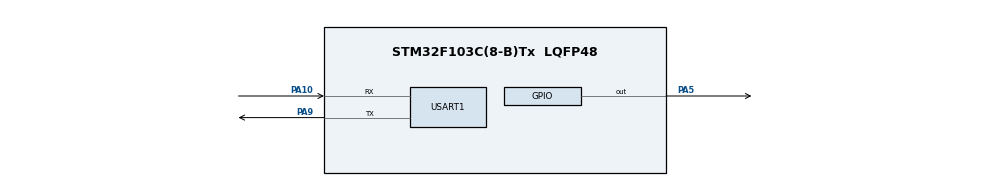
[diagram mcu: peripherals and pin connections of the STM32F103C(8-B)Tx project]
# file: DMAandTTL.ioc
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Dma.Request0=USART1_TX
Dma.Request1=USART1_RX
Dma.USART1_RX.1.Direction=DMA_PERIPH_TO_MEMORY
Dma.USART1_RX.1.Instance=DMA1_Channel5
Dma.USART1_RX.1.MemDataAlignment=DMA_MDATAALIGN_BYTE
Dma.USART1_RX.1.MemInc=DMA_MINC_ENABLE
Dma.USART1_RX.1.Mode=DMA_NORMAL
Dma.USART1_RX.1.PeriphDataAlignment=DMA_PDATAALIGN_BYTE
Dma.USART1_RX.1.PeriphInc=DMA_PINC_DISABLE
Dma.USART1_RX.1.Priority=DMA_PRIORITY_LOW
Dma.USART1_TX.0.Direction=DMA_MEMORY_TO_PERIPH
Dma.USART1_TX.0.Instance=DMA1_Channel4
Dma.USART1_TX.0.MemDataAlignment=DMA_MDATAALIGN_BYTE
Dma.USART1_TX.0.MemInc=DMA_MINC_ENABLE
Dma.USART1_TX.0.Mode=DMA_NORMAL
Dma.USART1_TX.0.PeriphDataAlignment=DMA_PDATAALIGN_BYTE
Dma.USART1_TX.0.PeriphInc=DMA_PINC_DISABLE
Dma.USART1_TX.0.Priority=DMA_PRIORITY_LOW
Mcu.Family=STM32F1
Mcu.Name=STM32F103C(8-B)Tx
Mcu.Package=LQFP48
NVIC.DMA1_Channel4_IRQn=true\:0\:0\:false\:false\:true\:false\:true\:true
NVIC.DMA1_Channel5_IRQn=true\:0\:0\:false\:false\:true\:false\:true\:true
NVIC.PriorityGroup=NVIC_PRIORITYGROUP_4
NVIC.USART1_IRQn=true\:0\:0\:false\:false\:true\:false\:true\:true
PA10.Mode=Asynchronous
PA10.Signal=USART1_RX
PA13.Mode=Serial_Wire
PA13.Signal=SYS_JTMS-SWDIO
PA14.Mode=Serial_Wire
PA14.Signal=SYS_JTCK-SWCLK
PA5.GPIO_ModeDefaultOutputPP=GPIO_MODE_OUTPUT_PP
PA5.GPIO_PuPd=GPIO_NOPULL
PA5.PinState=GPIO_PIN_SET
PA5.Signal=GPIO_Output
PA9.Mode=Asynchronous
PA9.Signal=USART1_TX
ProjectManager.HeapSize=0x200
ProjectManager.StackSize=0x400
ProjectManager.TargetToolchain=CMake
RCC.APB1Freq_Value=8000000
RCC.APB2Freq_Value=8000000
USART1.VirtualMode=VM_ASYNC
board=custom

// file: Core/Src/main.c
/* USER CODE BEGIN Header */
/**
  ******************************************************************************
  * @file           : main.c
  * @brief          : Main program body
  ******************************************************************************
  * @attention
  *
  * Copyright (c) 2026 STMicroelectronics.
  * All rights reserved.
  *
  * This software is licensed under terms that can be found in the LICENSE file
  * in the root directory of this software component.
  * If no LICENSE file comes with this software, it is provided AS-IS.
  *
  ******************************************************************************
  */
/* USER CODE END Header */
#include "main.h"

UART_HandleTypeDef huart1;
DMA_HandleTypeDef hdma_usart1_tx;
DMA_HandleTypeDef hdma_usart1_rx;

/* USER CODE BEGIN PV */
uint8_t message1[]= "Hello World! This is DMA test.\r\n";
uint16_t DMA_TX_SIZE = sizeof(message1) - 1;
volatile uint8_t uart_tx_done = 0; //串口发送完成标志
uint32_t last_tick = 0; //上次发送时间
uint32_t led_last_tick = 0;
uint8_t rx_buffer[64];
volatile uint8_t uart_rx_done = 0;
volatile uint16_t rx_len = 0;
/* USER CODE END PV */

void SystemClock_Config(void);
static void MX_GPIO_Init(void);
static void MX_DMA_Init(void);
static void MX_USART1_UART_Init(void);

int main(void)
{

  /* MCU Configuration--------------------------------------------------------*/

  /* Reset of all peripherals, Initializes the Flash interface and the Systick. */
  HAL_Init();

  /* Configure the system clock */
  SystemClock_Config();

  /* Initialize all configured peripherals */
  MX_GPIO_Init();
  MX_DMA_Init();
  MX_USART1_UART_Init();
  /* USER CODE BEGIN 2 */

  // //1.启动串口dma发送
  // if(HAL_UART_Transmit_DMA(&huart1, message1, DMA_TX_SIZE) != HAL_OK)
  // {
  //   Error_Handler();
  // }

  //
  if(HAL_UARTEx_ReceiveToIdle_DMA(&huart1,rx_buffer,sizeof(rx_buffer)) != HAL_OK)
  {
    Error_Handler();
  }

  //3.将时基时间更新为启动时间后，以启动时间为准
  last_tick = HAL_GetTick();
  led_last_tick = HAL_GetTick();

  /* USER CODE END 2 */

  /* Infinite loop */
  while (1)
  {

    /* USER CODE BEGIN 3 */
    // if(uart_tx_done && (HAL_GetTick() - last_tick >= 1000U))
    // {
    //   last_tick = HAL_GetTick();
    //   uart_tx_done = 0;

    //   //2.再次启动串口dma传输
    //   if(HAL_UART_Transmit_DMA(&huart1, message1, DMA_TX_SIZE) != HAL_OK)
    //   {
    //     Error_Handler();
    //   }
    // }

    if(HAL_GetTick() - led_last_tick >= 500U)
    {
      led_last_tick = HAL_GetTick();
      HAL_GPIO_TogglePin(GPIOA, GPIO_PIN_5);
    }

    if(uart_rx_done)
    {
      uart_rx_done = 0;
      //处理接收到的数据
      //这里简单的将接收到的数据再发送出去
      if(HAL_UART_Transmit_DMA(&huart1, rx_buffer, rx_len) != HAL_OK)
      {
        Error_Handler();
      }
    }

    if(uart_tx_done)
    {
      uart_tx_done = 0;
      //再次启动串口dma接收
      if(HAL_UARTEx_ReceiveToIdle_DMA(&huart1,rx_buffer,sizeof(rx_buffer)) != HAL_OK)
      {
        Error_Handler();
      }
    }

  }
  /* USER CODE END 3 */
}

void SystemClock_Config(void)
{
  RCC_OscInitTypeDef RCC_OscInitStruct = {0};
  RCC_ClkInitTypeDef RCC_ClkInitStruct = {0};

  /** Initializes the RCC Oscillators according to the specified parameters
  * in the RCC_OscInitTypeDef structure.
  */
  RCC_OscInitStruct.OscillatorType = RCC_OSCILLATORTYPE_HSI;
  RCC_OscInitStruct.HSIState = RCC_HSI_ON;
  RCC_OscInitStruct.HSICalibrationValue = RCC_HSICALIBRATION_DEFAULT;
  RCC_OscInitStruct.PLL.PLLState = RCC_PLL_NONE;
  if (HAL_RCC_OscConfig(&RCC_OscInitStruct) != HAL_OK)
  {
    Error_Handler();
  }

  /** Initializes the CPU, AHB and APB buses clocks
  */
  RCC_ClkInitStruct.ClockType = RCC_CLOCKTYPE_HCLK|RCC_CLOCKTYPE_SYSCLK
                              |RCC_CLOCKTYPE_PCLK1|RCC_CLOCKTYPE_PCLK2;
  RCC_ClkInitStruct.SYSCLKSource = RCC_SYSCLKSOURCE_HSI;
  RCC_ClkInitStruct.AHBCLKDivider = RCC_SYSCLK_DIV1;
  RCC_ClkInitStruct.APB1CLKDivider = RCC_HCLK_DIV1;
  RCC_ClkInitStruct.APB2CLKDivider = RCC_HCLK_DIV1;

  if (HAL_RCC_ClockConfig(&RCC_ClkInitStruct, FLASH_LATENCY_0) != HAL_OK)
  {
    Error_Handler();
  }
}

static void MX_USART1_UART_Init(void)
{

  huart1.Instance = USART1;
  huart1.Init.BaudRate = 115200;
  huart1.Init.WordLength = UART_WORDLENGTH_8B;
  huart1.Init.StopBits = UART_STOPBITS_1;
  huart1.Init.Parity = UART_PARITY_NONE;
  huart1.Init.Mode = UART_MODE_TX_RX;
  huart1.Init.HwFlowCtl = UART_HWCONTROL_NONE;
  huart1.Init.OverSampling = UART_OVERSAMPLING_16;
  if (HAL_UART_Init(&huart1) != HAL_OK)
  {
    Error_Handler();
  }

}

static void MX_DMA_Init(void)
{

  /* DMA controller clock enable */
  __HAL_RCC_DMA1_CLK_ENABLE();

  /* DMA interrupt init */
  /* DMA1_Channel4_IRQn interrupt configuration */
  HAL_NVIC_SetPriority(DMA1_Channel4_IRQn, 0, 0);
  HAL_NVIC_EnableIRQ(DMA1_Channel4_IRQn);
  /* DMA1_Channel5_IRQn interrupt configuration */
  HAL_NVIC_SetPriority(DMA1_Channel5_IRQn, 0, 0);
  HAL_NVIC_EnableIRQ(DMA1_Channel5_IRQn);

}

static void MX_GPIO_Init(void)
{
  GPIO_InitTypeDef GPIO_InitStruct = {0};

  /* GPIO Ports Clock Enable */
  __HAL_RCC_GPIOA_CLK_ENABLE();

  /*Configure GPIO pin Output Level */
  HAL_GPIO_WritePin(GPIOA, GPIO_PIN_5, GPIO_PIN_SET);

  /*Configure GPIO pin : PA5 */
  GPIO_InitStruct.Pin = GPIO_PIN_5;
  GPIO_InitStruct.Mode = GPIO_MODE_OUTPUT_PP;
  GPIO_InitStruct.Pull = GPIO_NOPULL;
  GPIO_InitStruct.Speed = GPIO_SPEED_FREQ_LOW;
  HAL_GPIO_Init(GPIOA, &GPIO_InitStruct);

}

/* USER CODE BEGIN 4 */
void HAL_UART_TxCpltCallback(UART_HandleTypeDef *huart)
{
    // 1. 判断是否为 USART1
    if(huart->Instance == USART1)
    {
      // 2. 如果是，将发送完成标志设置为1
      uart_tx_done = 1;
    }
}

void HAL_UARTEx_RxEventCallback(UART_HandleTypeDef *huart, uint16_t Size)
{
    // 1. 判断是否为 USART1
    if(huart->Instance == USART1)
    {
      if (HAL_UARTEx_GetRxEventType(huart) == HAL_UART_RXEVENT_IDLE ||
        HAL_UARTEx_GetRxEventType(huart) == HAL_UART_RXEVENT_TC)
      {
        rx_len = Size;
        uart_rx_done = 1;
      }
    }
}
/* USER CODE END 4 */

void Error_Handler(void)
{
  __disable_irq();
  while (1)
  {
  }
}
